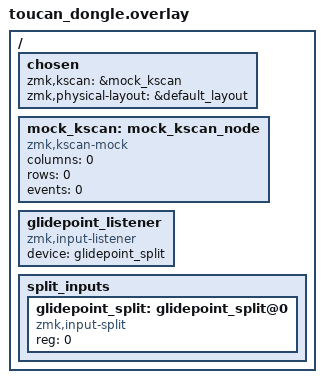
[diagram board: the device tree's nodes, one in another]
#include "toucan_common.dtsi"

/ {
    chosen {
        zmk,kscan = &mock_kscan;
        zmk,physical-layout = &default_layout;
    };

    /delete-node/ kscan_0;

    mock_kscan: mock_kscan_node {
        compatible = "zmk,kscan-mock";
        columns = <0>;
        rows = <0>;
        events = <0>;
    };

    /* Central side listener for trackpad data from peripherals */
    glidepoint_listener: glidepoint_listener {
        compatible = "zmk,input-listener";
        device = <&glidepoint_split>;
    };

    split_inputs {
        #address-cells = <1>;
        #size-cells = <0>;

        glidepoint_split: glidepoint_split@0 {
            compatible = "zmk,input-split";
            reg = <0>;
        };
    };
};
